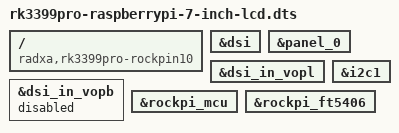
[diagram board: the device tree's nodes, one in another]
/dts-v1/;
/plugin/;

/ {
	compatible = "radxa,rk3399pro-rockpin10", "rockchip,rk3399pro";

	fragment@0 {
		target = <&dsi>;
		__overlay__ {
			status = "okay";
		};
	};

	fragment@1 {
		target = <&panel_0>;
		__overlay__ {
			status = "okay";
		};
	};

	fragment@2 {
		target = <&dsi_in_vopl>;
		__overlay__ {
			status = "okay";
		};
	};

	fragment@3 {
		target = <&dsi_in_vopb>;
		__overlay__ {
			status = "disabled";
		};
	};

	fragment@4 {
		target = <&i2c1>;
		__overlay__ {
			status = "okay";
		};
	};

	fragment@5 {
		target = <&rockpi_mcu>;
		__overlay__ {
			status = "okay";
		};
	};

	fragment@6 {
		target = <&rockpi_ft5406>;
		__overlay__ {
			status = "okay";
		};
	};
};
